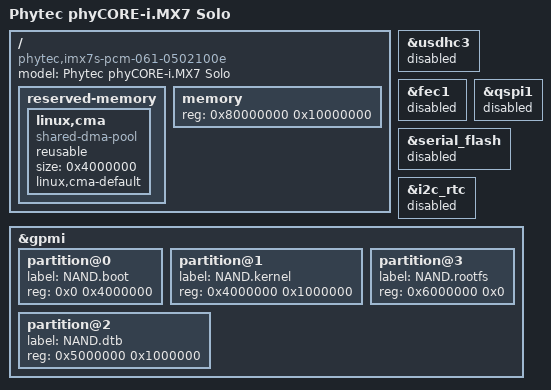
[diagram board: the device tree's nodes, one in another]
/*
 * Copyright (C) 2017 PHYTEC America, LLC
 *
 * This program is free software; you can redistribute it and/or modify
 * it under the terms of the GNU General Public License version 2 as
 * published by the Free Software Foundation.
 */

/ {
	model = "Phytec phyCORE-i.MX7 Solo";
	compatible = "phytec,imx7s-pcm-061-0502100e", "phytec,imx7-phycore-som", "fsl,imx7d";

	reserved-memory {
		#address-cells = <1>;
		#size-cells = <1>;
		ranges;

		/* global autoconfigured region for contiguous allocations */
		linux,cma {
			compatible = "shared-dma-pool";
			reusable;
			size = <0x4000000>;	/* 64MiB */
			linux,cma-default;
		};
	};

	memory {
		reg = <0x80000000 0x10000000>;	/* 256MB */
	};
};

/* eMMC not populated */
&usdhc3 {
	status = "disabled";
};

/* No PHY on SOM */
&fec1 {
	status = "disabled";
};

/* No SPI NOR */
&qspi1 {
	status = "disabled";
};

&serial_flash {
	status = "disabled";
};

/* No external RTC */
&i2c_rtc {
	status = "disabled";
};

/* NAND Configuration */
&gpmi {
	status = "okay";

	partition@0 {
		label = "NAND.boot";
		reg = <0x0 0x4000000>;
	};

	partition@1 {
		label = "NAND.kernel";
		reg = <0x4000000 0x1000000>;
	};

	partition@2 {
		label = "NAND.dtb";
		reg = <0x5000000 0x1000000>;
	};

	partition@3 {
		label = "NAND.rootfs";
		reg = <0x6000000 0x0>;	/* To end of device */
	};
};
